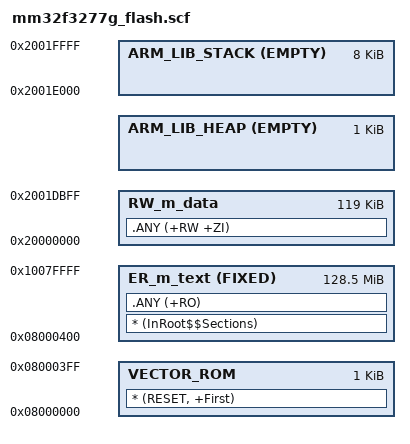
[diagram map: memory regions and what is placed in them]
LR_m_text 0x08000000 0x08080000
{
	VECTOR_ROM 0x08000000 0x00000400
	{
		* (RESET, +First)
	}
	ER_m_text 0x08000400 FIXED 0x0807FC00
	{
		* (InRoot$$Sections)
		.ANY (+RO)
	}
	RW_m_data 0x20000000 0x0001DC00
	{
		.ANY (+RW +ZI)
	}
	ARM_LIB_HEAP +0 EMPTY 0x0400
	{
	}
	ARM_LIB_STACK 0x20020000 EMPTY -0x2000
	{
	}
}
